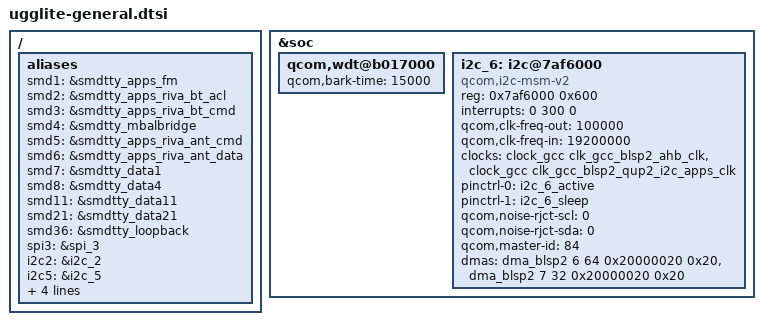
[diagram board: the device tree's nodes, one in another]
/*
 * Copyright (c) 2015-2016, The Linux Foundation. All rights reserved.
 * Copyright (C) 2018 XiaoMi, Inc.
 *
 * This program is free software; you can redistribute it and/or modify
 * it under the terms of the GNU General Public License version 2 and
 * only version 2 as published by the Free Software Foundation.
 *
 * This program is distributed in the hope that it will be useful,
 * but WITHOUT ANY WARRANTY; without even the implied warranty of
 * MERCHANTABILITY or FITNESS FOR A PARTICULAR PURPOSE.  See the
 * GNU General Public License for more details.
 */
/ {
	aliases {
		/* smdtty devices */
		smd1 = &smdtty_apps_fm;
		smd2 = &smdtty_apps_riva_bt_acl;
		smd3 = &smdtty_apps_riva_bt_cmd;
		smd4 = &smdtty_mbalbridge;
		smd5 = &smdtty_apps_riva_ant_cmd;
		smd6 = &smdtty_apps_riva_ant_data;
		smd7 = &smdtty_data1;
		smd8 = &smdtty_data4;
		smd11 = &smdtty_data11;
		smd21 = &smdtty_data21;
		smd36 = &smdtty_loopback;
		spi3 = &spi_3;
		i2c2 = &i2c_2;
		i2c5 = &i2c_5;
		i2c3 = &i2c_3;
		i2c6 = &i2c_6;
		sdhc1 = &sdhc_1; /* SDC1 eMMC slot */
		sdhc2 = &sdhc_2; /* SDC2 for SD card */
	};
};

/delete-node/ &led_flash0;
/delete-node/ &pmi8937_fg;
/delete-node/ &pmi8937_charger;

&soc {
	qcom,wdt@b017000 {
		qcom,bark-time = <15000>;
	};

	i2c_6: i2c@7af6000 {
		compatible = "qcom,i2c-msm-v2";
		#address-cells = <1>;
		#size-cells = <0>;
		reg-names = "qup_phys_addr";
		reg = <0x7af6000 0x600>;
		interrupt-names = "qup_irq";
		interrupts = <0 300 0>;
		qcom,clk-freq-out = <100000>;
		qcom,clk-freq-in  = <19200000>;
		clock-names = "iface_clk", "core_clk";
		clocks = <&clock_gcc clk_gcc_blsp2_ahb_clk>,
			<&clock_gcc clk_gcc_blsp2_qup2_i2c_apps_clk>;

		pinctrl-names = "i2c_active", "i2c_sleep";
		pinctrl-0 = <&i2c_6_active>;
		pinctrl-1 = <&i2c_6_sleep>;
		qcom,noise-rjct-scl = <0>;
		qcom,noise-rjct-sda = <0>;
		qcom,master-id = <84>;
		dmas = <&dma_blsp2 6 64 0x20000020 0x20>,
			<&dma_blsp2 7 32 0x20000020 0x20>;
		dma-names = "tx", "rx";
		status = "ok";
	};
};
